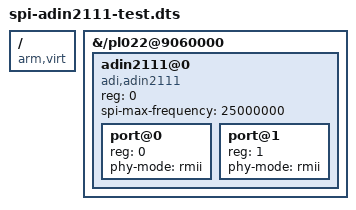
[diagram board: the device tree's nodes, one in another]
/dts-v1/;
/plugin/;

/ {
    compatible = "arm,virt";
    
    fragment@0 {
        target-path = "/pl022@9060000";
        __overlay__ {
            status = "okay";
            
            adin2111@0 {
                compatible = "adi,adin2111";
                reg = <0>;
                spi-max-frequency = <25000000>;
                
                port@0 {
                    reg = <0>;
                    phy-mode = "rmii";
                };
                
                port@1 {
                    reg = <1>;
                    phy-mode = "rmii";
                };
            };
        };
    };
};
